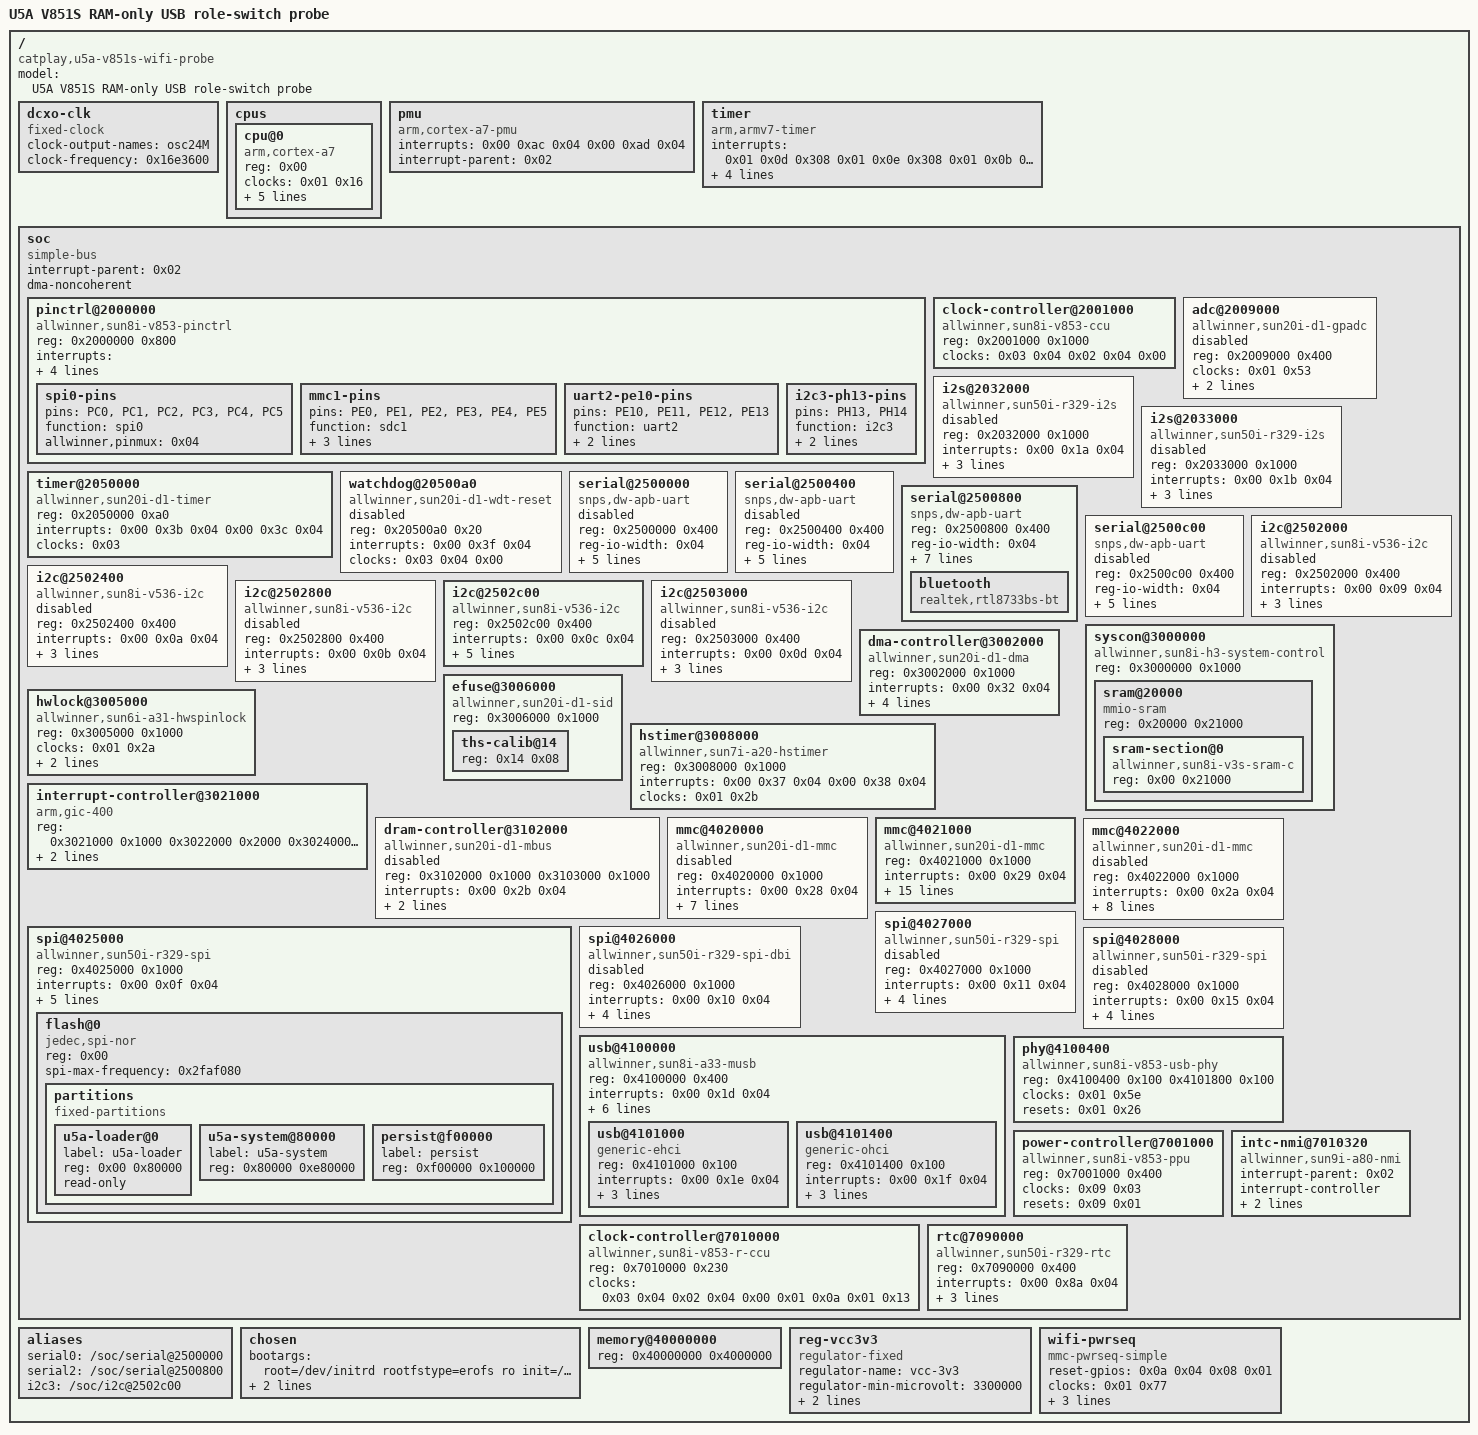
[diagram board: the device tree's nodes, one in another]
/dts-v1/;

/ {
	#address-cells = <0x01>;
	#size-cells = <0x01>;
	model = "U5A V851S RAM-only USB role-switch probe";
	compatible = "catplay,u5a-v851s-wifi-probe", "allwinner,sun8i-v853";

	dcxo-clk {
		compatible = "fixed-clock";
		clock-output-names = "osc24M";
		#clock-cells = <0x00>;
		clock-frequency = <0x16e3600>;
		phandle = <0x03>;
	};

	cpus {
		#address-cells = <0x01>;
		#size-cells = <0x00>;

		cpu@0 {
			device_type = "cpu";
			compatible = "arm,cortex-a7", "arm,armv7";
			reg = <0x00>;
			clocks = <0x01 0x16>;
			clock-names = "cpu";
			clock-frequency = <0x365c0400>;
			clock-latency = <0x30d40>;
			cooling-min-level = <0x05>;
			cooling-max-level = <0x00>;
			#cooling-cells = <0x02>;
			dynamic-power-coefficient = <0x8e>;
		};
	};

	pmu {
		compatible = "arm,cortex-a7-pmu";
		interrupts = <0x00 0xac 0x04 0x00 0xad 0x04>;
		interrupt-parent = <0x02>;
	};

	timer {
		compatible = "arm,armv7-timer";
		interrupts = <0x01 0x0d 0x308 0x01 0x0e 0x308 0x01 0x0b 0x308 0x01 0x0a 0x308>;
		clock-frequency = <0x16e3600>;
		interrupt-parent = <0x02>;
		arm,cpu-registers-not-fw-configured;
		arm,no-tick-in-suspend;
	};

	soc {
		compatible = "simple-bus";
		ranges;
		interrupt-parent = <0x02>;
		#address-cells = <0x01>;
		#size-cells = <0x01>;
		dma-noncoherent;

		pinctrl@2000000 {
			compatible = "allwinner,sun8i-v853-pinctrl";
			reg = <0x2000000 0x800>;
			interrupts = <0x00 0x43 0x04 0x00 0x47 0x04 0x00 0x49 0x04 0x00 0x4b 0x04 0x00 0x4d 0x04 0x00 0x4f 0x04 0x00 0x51 0x04 0x00 0x53 0x04>;
			clocks = <0x01 0x1a 0x03 0x04 0x00>;
			clock-names = "apb", "hosc", "losc";
			gpio-controller;
			interrupt-controller;
			#gpio-cells = <0x03>;
			#interrupt-cells = <0x03>;
			phandle = <0x0a>;

			spi0-pins {
				pins = "PC0", "PC1", "PC2", "PC3", "PC4", "PC5";
				function = "spi0";
				allwinner,pinmux = <0x04>;
				phandle = <0x7e01>;
			};

			mmc1-pins {
				pins = "PE0", "PE1", "PE2", "PE3", "PE4", "PE5";
				function = "sdc1";
				allwinner,pinmux = <0x06>;
				drive-strength = <0x1e>;
				bias-pull-up;
				phandle = <0x07>;
			};

			uart2-pe10-pins {
				pins = "PE10", "PE11", "PE12", "PE13";
				function = "uart2";
				allwinner,pinmux = <0x06>;
				bias-pull-up;
				phandle = <0x51>;
			};

			i2c3-ph13-pins {
				pins = "PH13", "PH14";
				function = "i2c3";
				allwinner,pinmux = <0x05>;
				bias-pull-up;
				phandle = <0x52>;
			};
		};

		clock-controller@2001000 {
			compatible = "allwinner,sun8i-v853-ccu";
			reg = <0x2001000 0x1000>;
			clocks = <0x03 0x04 0x02 0x04 0x00>;
			clock-names = "hosc", "iosc", "losc";
			#clock-cells = <0x01>;
			#reset-cells = <0x01>;
			phandle = <0x01>;
		};

		adc@2009000 {
			compatible = "allwinner,sun20i-d1-gpadc";
			reg = <0x2009000 0x400>;
			clocks = <0x01 0x53>;
			resets = <0x01 0x20>;
			interrupts = <0x00 0x39 0x04>;
			status = "disabled";
			#io-channel-cells = <0x01>;
		};

		i2s@2032000 {
			compatible = "allwinner,sun50i-r329-i2s";
			reg = <0x2032000 0x1000>;
			interrupts = <0x00 0x1a 0x04>;
			clocks = <0x01 0x57 0x01 0x55>;
			clock-names = "apb", "mod";
			resets = <0x01 0x22>;
			dmas = <0x05 0x03 0x05 0x03>;
			dma-names = "rx", "tx";
			status = "disabled";
			#sound-dai-cells = <0x00>;
		};

		i2s@2033000 {
			compatible = "allwinner,sun50i-r329-i2s";
			reg = <0x2033000 0x1000>;
			interrupts = <0x00 0x1b 0x04>;
			clocks = <0x01 0x58 0x01 0x56>;
			clock-names = "apb", "mod";
			resets = <0x01 0x23>;
			dmas = <0x05 0x04 0x05 0x04>;
			dma-names = "rx", "tx";
			status = "disabled";
			#sound-dai-cells = <0x00>;
		};

		timer@2050000 {
			compatible = "allwinner,sun20i-d1-timer", "allwinner,sun8i-a23-timer";
			reg = <0x2050000 0xa0>;
			interrupts = <0x00 0x3b 0x04 0x00 0x3c 0x04>;
			clocks = <0x03>;
		};

		watchdog@20500a0 {
			compatible = "allwinner,sun20i-d1-wdt-reset", "allwinner,sun20i-d1-wdt";
			reg = <0x20500a0 0x20>;
			interrupts = <0x00 0x3f 0x04>;
			clocks = <0x03 0x04 0x00>;
			clock-names = "hosc", "losc";
			status = "reserved";
		};

		serial@2500000 {
			compatible = "snps,dw-apb-uart";
			reg = <0x2500000 0x400>;
			reg-io-width = <0x04>;
			reg-shift = <0x02>;
			interrupts = <0x00 0x02 0x04>;
			clocks = <0x01 0x3e>;
			resets = <0x01 0x11>;
			dmas = <0x05 0x0e 0x05 0x0e>;
			dma-names = "rx", "tx";
			status = "disabled";
		};

		serial@2500400 {
			compatible = "snps,dw-apb-uart";
			reg = <0x2500400 0x400>;
			reg-io-width = <0x04>;
			reg-shift = <0x02>;
			interrupts = <0x00 0x03 0x04>;
			clocks = <0x01 0x3f>;
			resets = <0x01 0x12>;
			dmas = <0x05 0x0f 0x05 0x0f>;
			dma-names = "rx", "tx";
			status = "disabled";
		};

		serial@2500800 {
			compatible = "snps,dw-apb-uart";
			reg = <0x2500800 0x400>;
			reg-io-width = <0x04>;
			reg-shift = <0x02>;
			interrupts = <0x00 0x04 0x04>;
			clocks = <0x01 0x40>;
			resets = <0x01 0x13>;
			dmas = <0x05 0x10 0x05 0x10>;
			dma-names = "rx", "tx";
			status = "okay";
			pinctrl-0 = <0x51>;
			pinctrl-names = "default";
			uart-has-rtscts;

			bluetooth {
				compatible = "realtek,rtl8733bs-bt";
			};
		};

		serial@2500c00 {
			compatible = "snps,dw-apb-uart";
			reg = <0x2500c00 0x400>;
			reg-io-width = <0x04>;
			reg-shift = <0x02>;
			interrupts = <0x00 0x05 0x04>;
			clocks = <0x01 0x41>;
			resets = <0x01 0x14>;
			dmas = <0x05 0x11 0x05 0x11>;
			dma-names = "rx", "tx";
			status = "disabled";
		};

		i2c@2502000 {
			compatible = "allwinner,sun8i-v536-i2c", "allwinner,sun6i-a31-i2c";
			reg = <0x2502000 0x400>;
			interrupts = <0x00 0x09 0x04>;
			clocks = <0x01 0x42>;
			resets = <0x01 0x15>;
			dmas = <0x05 0x2b 0x05 0x2b>;
			dma-names = "rx", "tx";
			status = "disabled";
			#address-cells = <0x01>;
			#size-cells = <0x00>;
		};

		i2c@2502400 {
			compatible = "allwinner,sun8i-v536-i2c", "allwinner,sun6i-a31-i2c";
			reg = <0x2502400 0x400>;
			interrupts = <0x00 0x0a 0x04>;
			clocks = <0x01 0x43>;
			resets = <0x01 0x16>;
			dmas = <0x05 0x2c 0x05 0x2c>;
			dma-names = "rx", "tx";
			status = "disabled";
			#address-cells = <0x01>;
			#size-cells = <0x00>;
		};

		i2c@2502800 {
			compatible = "allwinner,sun8i-v536-i2c", "allwinner,sun6i-a31-i2c";
			reg = <0x2502800 0x400>;
			interrupts = <0x00 0x0b 0x04>;
			clocks = <0x01 0x44>;
			resets = <0x01 0x17>;
			dmas = <0x05 0x2d 0x05 0x2d>;
			dma-names = "rx", "tx";
			status = "disabled";
			#address-cells = <0x01>;
			#size-cells = <0x00>;
		};

		i2c@2502c00 {
			compatible = "allwinner,sun8i-v536-i2c", "allwinner,sun6i-a31-i2c";
			reg = <0x2502c00 0x400>;
			interrupts = <0x00 0x0c 0x04>;
			clocks = <0x01 0x45>;
			resets = <0x01 0x18>;
			dmas = <0x05 0x2e 0x05 0x2e>;
			dma-names = "rx", "tx";
			status = "okay";
			clock-frequency = <100000>;
			pinctrl-0 = <0x52>;
			pinctrl-names = "default";
			#address-cells = <0x01>;
			#size-cells = <0x00>;
		};

		i2c@2503000 {
			compatible = "allwinner,sun8i-v536-i2c", "allwinner,sun6i-a31-i2c";
			reg = <0x2503000 0x400>;
			interrupts = <0x00 0x0d 0x04>;
			clocks = <0x01 0x46>;
			resets = <0x01 0x19>;
			dmas = <0x05 0x2f 0x05 0x2f>;
			dma-names = "rx", "tx";
			status = "disabled";
			#address-cells = <0x01>;
			#size-cells = <0x00>;
		};

		syscon@3000000 {
			compatible = "allwinner,sun8i-h3-system-control";
			reg = <0x3000000 0x1000>;
			ranges;
			#address-cells = <0x01>;
			#size-cells = <0x01>;

			sram@20000 {
				compatible = "mmio-sram";
				reg = <0x20000 0x21000>;
				#address-cells = <0x01>;
				#size-cells = <0x01>;
				ranges = <0x00 0x20000 0x21000>;

				sram-section@0 {
					compatible = "allwinner,sun8i-v3s-sram-c", "allwinner,sun4i-a10-sram-c1";
					reg = <0x00 0x21000>;
				};
			};
		};

		dma-controller@3002000 {
			compatible = "allwinner,sun20i-d1-dma";
			reg = <0x3002000 0x1000>;
			interrupts = <0x00 0x32 0x04>;
			clocks = <0x01 0x27 0x01 0x31>;
			clock-names = "bus", "mbus";
			resets = <0x01 0x06>;
			dma-channels = <0x10>;
			dma-requests = <0x30>;
			#dma-cells = <0x01>;
			phandle = <0x05>;
		};

		hwlock@3005000 {
			compatible = "allwinner,sun6i-a31-hwspinlock";
			reg = <0x3005000 0x1000>;
			clocks = <0x01 0x2a>;
			clock-names = "ahb";
			resets = <0x01 0x09>;
			reset-names = "ahb";
			interrupts = <0x00 0x36 0x04>;
		};

		efuse@3006000 {
			compatible = "allwinner,sun20i-d1-sid";
			reg = <0x3006000 0x1000>;
			#address-cells = <0x01>;
			#size-cells = <0x01>;

			ths-calib@14 {
				reg = <0x14 0x08>;
			};
		};

		hstimer@3008000 {
			compatible = "allwinner,sun7i-a20-hstimer";
			reg = <0x3008000 0x1000>;
			interrupts = <0x00 0x37 0x04 0x00 0x38 0x04>;
			clocks = <0x01 0x2b>;
		};

		interrupt-controller@3021000 {
			compatible = "arm,gic-400";
			reg = <0x3021000 0x1000 0x3022000 0x2000 0x3024000 0x2000 0x3026000 0x2000>;
			interrupts = <0x01 0x09 0x304>;
			interrupt-controller;
			#interrupt-cells = <0x03>;
			phandle = <0x02>;
		};

		dram-controller@3102000 {
			compatible = "allwinner,sun20i-d1-mbus";
			reg = <0x3102000 0x1000 0x3103000 0x1000>;
			reg-names = "mbus", "dram";
			interrupts = <0x00 0x2b 0x04>;
			clocks = <0x01 0x1c 0x01 0x30 0x01 0x37>;
			clock-names = "mbus", "dram", "bus";
			dma-ranges = <0x00 0x40000000 0x80000000>;
			#address-cells = <0x01>;
			#size-cells = <0x01>;
			#interconnect-cells = <0x01>;
			status = "disabled";
		};

		mmc@4020000 {
			compatible = "allwinner,sun20i-d1-mmc";
			reg = <0x4020000 0x1000>;
			interrupts = <0x00 0x28 0x04>;
			clocks = <0x01 0x3b 0x01 0x38>;
			clock-names = "ahb", "mmc";
			resets = <0x01 0x0e>;
			reset-names = "ahb";
			no-sdio;
			no-mmc;
			cap-sd-highspeed;
			max-frequency = <0x8f0d180>;
			mmc-ddr-1_8v;
			status = "disabled";
			#address-cells = <0x01>;
			#size-cells = <0x00>;
		};

		mmc@4021000 {
			compatible = "allwinner,sun20i-d1-mmc";
			reg = <0x4021000 0x1000>;
			interrupts = <0x00 0x29 0x04>;
			clocks = <0x01 0x3c 0x01 0x39>;
			clock-names = "ahb", "mmc";
			resets = <0x01 0x0f>;
			reset-names = "ahb";
			cap-sd-highspeed;
			cap-mmc-highspeed;
			max-frequency = <0x2faf080>;
			status = "okay";
			#address-cells = <0x01>;
			#size-cells = <0x00>;
			bus-width = <0x04>;
			non-removable;
			no-sd;
			no-mmc;
			cap-sdio-irq;
			keep-power-in-suspend;
			mmc-pwrseq = <0x06>;
			vmmc-supply = <0x50>;
			vqmmc-supply = <0x50>;
			pinctrl-0 = <0x07>;
			pinctrl-names = "default";
		};

		mmc@4022000 {
			compatible = "allwinner,sun20i-d1-mmc";
			reg = <0x4022000 0x1000>;
			interrupts = <0x00 0x2a 0x04>;
			clocks = <0x01 0x3d 0x01 0x3a>;
			clock-names = "ahb", "mmc";
			resets = <0x01 0x10>;
			reset-names = "ahb";
			no-sdio;
			no-sd;
			cap-mmc-highspeed;
			max-frequency = <0x8f0d180>;
			mmc-ddr-1_8v;
			mmc-ddr-3_3v;
			status = "disabled";
			#address-cells = <0x01>;
			#size-cells = <0x00>;
		};

		spi@4025000 {
			compatible = "allwinner,sun50i-r329-spi";
			reg = <0x4025000 0x1000>;
			interrupts = <0x00 0x0f 0x04>;
			clocks = <0x01 0x4b 0x01 0x47>;
			clock-names = "ahb", "mod";
			resets = <0x01 0x1a>;
			dmas = <0x05 0x16 0x05 0x16>;
			dma-names = "rx", "tx";
			num-cs = <0x01>;
			status = "okay";
			#address-cells = <0x01>;
			#size-cells = <0x00>;
			pinctrl-names = "default";
			pinctrl-0 = <0x7e01>;

			flash@0 {
				compatible = "jedec,spi-nor";
				reg = <0x00>;
				spi-max-frequency = <0x2faf080>;

				partitions {
					compatible = "fixed-partitions";
					#address-cells = <0x01>;
					#size-cells = <0x01>;

					u5a-loader@0 {
						label = "u5a-loader";
						reg = <0x00 0x80000>;
						read-only;
					};

					u5a-system@80000 {
						label = "u5a-system";
						reg = <0x80000 0xe80000>;
					};

					persist@f00000 {
						label = "persist";
						reg = <0xf00000 0x100000>;
					};
				};
			};
		};

		spi@4026000 {
			compatible = "allwinner,sun50i-r329-spi-dbi", "allwinner,sun50i-r329-spi";
			reg = <0x4026000 0x1000>;
			interrupts = <0x00 0x10 0x04>;
			clocks = <0x01 0x4c 0x01 0x48>;
			clock-names = "ahb", "mod";
			resets = <0x01 0x1b>;
			dmas = <0x05 0x17 0x05 0x17>;
			dma-names = "rx", "tx";
			num-cs = <0x01>;
			status = "disabled";
			#address-cells = <0x01>;
			#size-cells = <0x00>;
		};

		spi@4027000 {
			compatible = "allwinner,sun50i-r329-spi";
			reg = <0x4027000 0x1000>;
			interrupts = <0x00 0x11 0x04>;
			clocks = <0x01 0x4d 0x01 0x49>;
			clock-names = "ahb", "mod";
			resets = <0x01 0x1c>;
			dmas = <0x05 0x18 0x05 0x18>;
			dma-names = "rx", "tx";
			num-cs = <0x01>;
			status = "disabled";
			#address-cells = <0x01>;
			#size-cells = <0x00>;
		};

		spi@4028000 {
			compatible = "allwinner,sun50i-r329-spi";
			reg = <0x4028000 0x1000>;
			interrupts = <0x00 0x15 0x04>;
			clocks = <0x01 0x4e 0x01 0x4a>;
			clock-names = "ahb", "mod";
			resets = <0x01 0x1d>;
			dmas = <0x05 0x19 0x05 0x19>;
			dma-names = "rx", "tx";
			num-cs = <0x01>;
			status = "disabled";
			#address-cells = <0x01>;
			#size-cells = <0x00>;
		};

		usb@4100000 {
			compatible = "allwinner,sun8i-a33-musb";
			reg = <0x4100000 0x400>;
			interrupts = <0x00 0x1d 0x04>;
			interrupt-names = "mc";
			clocks = <0x01 0x61>;
			resets = <0x01 0x29>;
			extcon = <0x08 0x00>;
			phys = <0x08 0x00>;
			phy-names = "usb";
			status = "okay";
			dr_mode = "peripheral";
			usb-role-switch;
			#address-cells = <0x01>;
			#size-cells = <0x01>;
			ranges;

			usb@4101000 {
				compatible = "generic-ehci";
				reg = <0x4101000 0x100>;
				interrupts = <0x00 0x1e 0x04>;
				clocks = <0x01 0x5f 0x01 0x60 0x01 0x5e>;
				resets = <0x01 0x27 0x01 0x28>;
				phys = <0x08 0x00>;
				phy-names = "usb";
			};

			usb@4101400 {
				compatible = "generic-ohci";
				reg = <0x4101400 0x100>;
				interrupts = <0x00 0x1f 0x04>;
				clocks = <0x01 0x5f 0x01 0x5e>;
				resets = <0x01 0x27>;
				phys = <0x08 0x00>;
				phy-names = "usb";
			};
		};

		phy@4100400 {
			compatible = "allwinner,sun8i-v853-usb-phy";
			reg = <0x4100400 0x100 0x4101800 0x100>;
			reg-names = "phy_ctrl", "pmu0";
			clocks = <0x01 0x5e>;
			clock-names = "usb0_phy";
			resets = <0x01 0x26>;
			reset-names = "usb0_reset";
			status = "okay";
			#phy-cells = <0x01>;
			phandle = <0x08>;
		};


		power-controller@7001000 {
			compatible = "allwinner,sun8i-v853-ppu";
			reg = <0x7001000 0x400>;
			clocks = <0x09 0x03>;
			resets = <0x09 0x01>;
			#power-domain-cells = <0x01>;
		};

		clock-controller@7010000 {
			compatible = "allwinner,sun8i-v853-r-ccu";
			reg = <0x7010000 0x230>;
			clocks = <0x03 0x04 0x02 0x04 0x00 0x01 0x0a 0x01 0x13>;
			clock-names = "hosc", "iosc", "losc", "pll-periph", "pll-audio";
			#clock-cells = <0x01>;
			#reset-cells = <0x01>;
			phandle = <0x09>;
		};

		intc-nmi@7010320 {
			compatible = "allwinner,sun9i-a80-nmi";
			interrupt-parent = <0x02>;
			#interrupt-cells = <0x02>;
			#address-cells = <0x00>;
			interrupt-controller;
			reg = <0x7010320 0x0c>;
			interrupts = <0x00 0x88 0x04>;
		};

		rtc@7090000 {
			compatible = "allwinner,sun50i-r329-rtc";
			reg = <0x7090000 0x400>;
			interrupts = <0x00 0x8a 0x04>;
			clocks = <0x09 0x04>;
			clock-names = "bus";
			resets = <0x09 0x02>;
			wakeup-source;
			#clock-cells = <0x01>;
			phandle = <0x04>;
		};
	};

	aliases {
		serial0 = "/soc/serial@2500000";
		serial2 = "/soc/serial@2500800";
		i2c3 = "/soc/i2c@2502c00";
	};

	chosen {
		bootargs = "root=/dev/initrd rootfstype=erofs ro init=/sbin/u5a-init u5a.mode=car console=ttyGS0,115200 earlycon=uart8250,mmio32,0x02500000 loglevel=5 clk_ignore_unused panic=0";
		linux,initrd-start = <0x43400000>;
		linux,initrd-end = <0x43d5e000>;
	};

	memory@40000000 {
		device_type = "memory";
		reg = <0x40000000 0x4000000>;
	};

	reg-vcc3v3 {
		compatible = "regulator-fixed";
		regulator-name = "vcc-3v3";
		regulator-min-microvolt = <3300000>;
		regulator-max-microvolt = <3300000>;
		regulator-always-on;
		phandle = <0x50>;
	};

	wifi-pwrseq {
		compatible = "mmc-pwrseq-simple";
		reset-gpios = <0x0a 0x04 0x08 0x01>;
		clocks = <0x01 0x77>;
		clock-names = "ext_clock";
		assigned-clocks = <0x01 0x77>;
		assigned-clock-parents = <0x04 0x00>;
		post-power-on-delay-ms = <0xc8>;
		phandle = <0x06>;
	};
};
